# HDSC_HC32M140FX register map
Vendor: HDSC Co.Ltd; Series: ARMCM0P; File version: 1.2
CPU: CM0 r0p0, little endian, no MPU, no FPU, 3 interrupt priority bits
Registers are 8-bit, read-write, reset 0x0 unless marked. A register's access mark holds for its fields unless they carry their own. Offsets are from the block's base; [hi:lo] are bit positions; {n}, {i} and the like mark numbered series; 'fields as' and 'values as' point back to an identical list.

## CLOCK_COUNTER
Base 0x4003A000
0x00 CNTRD ro
  [5:0] CNT
0x01 CNTRL
  [5:0] RLC
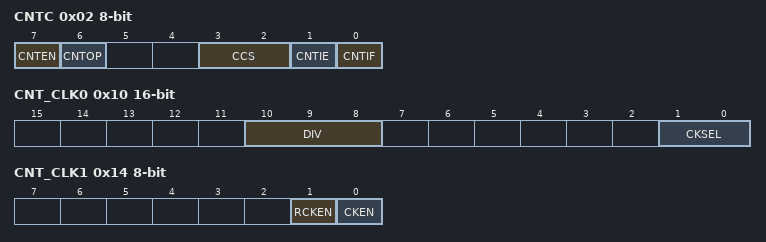
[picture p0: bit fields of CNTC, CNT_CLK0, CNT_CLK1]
0x02 CNTC
  [7] CNTEN, [6] CNTOP ro, [3:2] CCS, [1] CNTIE, [0] CNTIF
0x10 CNT_CLK0 16-bit
  [10:8] DIV, [1:0] CKSEL
0x14 CNT_CLK1
  [1] RCKEN ro, [0] CKEN

## CTIOSEL03
Base 0x40025100
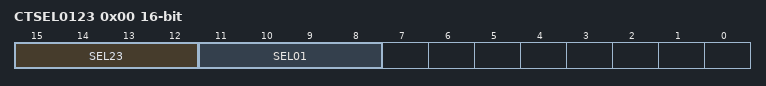
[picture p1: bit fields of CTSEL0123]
0x00 CTSEL0123 16-bit
  [15:12] SEL23, [11:8] SEL01

## CTSSSR
Base 0x40025F00
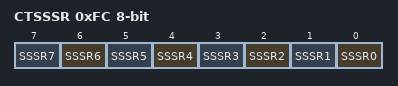
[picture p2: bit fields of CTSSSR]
0xFC CTSSSR
  [n] SSSR{n} wo (n=0..7)

## CT0_PPG — desc CT_PPG
Base 0x40025000
Same registers: CT1_PPG 0x40025040, CT2_PPG 0x40025080, CT3_PPG 0x400250C0
0x00 LWRR 16-bit
0x04 HWRR 16-bit
0x08 TCNT 16-bit ro
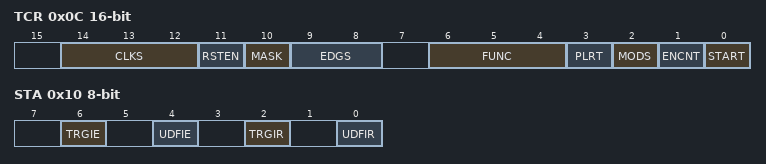
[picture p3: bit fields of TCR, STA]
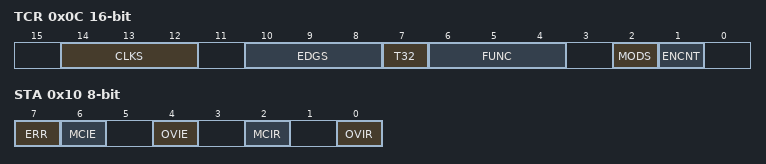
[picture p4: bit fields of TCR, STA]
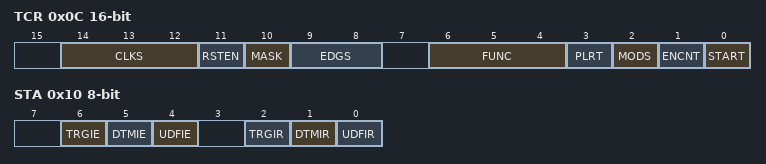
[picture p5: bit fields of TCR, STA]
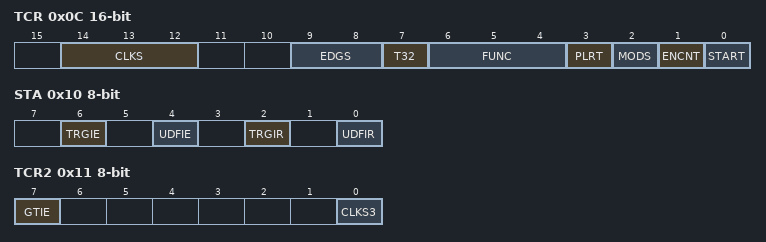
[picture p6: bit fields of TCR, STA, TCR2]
0x0C TCR 16-bit
  [14:12] CLKS, [11] RSTEN, [10] MASK, [9:8] EDGS, [6:4] FUNC, [3] PLRT, [2] MODS, [1] ENCNT, [0] START
0x10 STA
  [6] TRGIE, [4] UDFIE, [2] TRGIR, [0] UDFIR
0x11 TCR2
  [0] CLKS3

## CT0_PWC — desc CT_PWC
Base 0x40025000; alternate view of CT0_PPG
0x04 DBUF 16-bit ro (reset mask 0xFF)
0x0C TCR 16-bit
  [14:12] CLKS, [10:8] EDGS, [7] T32, [6:4] FUNC, [2] MODS, [1] ENCNT
0x10 STA
  [7] ERR ro, [6] MCIE, [4] OVIE, [2] MCIR ro, [0] OVIR
0x11 TCR2
  [0] CLKS3

## CT1_PWC — desc CT_PWC
Base 0x40025040; alternate view of CT1_PPG
Registers as CT0_PWC.

## CT2_PWC — desc CT_PWC
Base 0x40025080; alternate view of CT2_PPG
Registers as CT0_PWC.

## CT3_PWC — desc CT_PWC
Base 0x400250C0; alternate view of CT3_PPG
Registers as CT0_PWC.

## CT0_PWM — desc CT_PWM
Base 0x40025000; alternate view of CT0_PPG
0x00 CSR 16-bit
0x04 DUT 16-bit
0x08 TCNT 16-bit ro
0x0C TCR 16-bit
  [14:12] CLKS, [11] RSTEN, [10] MASK, [9:8] EDGS, [6:4] FUNC, [3] PLRT, [2] MODS, [1] ENCNT, [0] START
0x10 STA
  [6] TRGIE, [5] DTMIE, [4] UDFIE, [2] TRGIR, [1] DTMIR, [0] UDFIR
0x11 TCR2
  [0] CLKS3

## CT1_PWM — desc CT_PWM
Base 0x40025040; alternate view of CT1_PPG
Registers as CT0_PWM.

## CT2_PWM — desc CT_PWM
Base 0x40025080; alternate view of CT2_PPG
Registers as CT0_PWM.

## CT3_PWM — desc CT_PWM
Base 0x400250C0; alternate view of CT3_PPG
Registers as CT0_PWM.

## CT0_RT — desc CT_RT
Base 0x40025000; alternate view of CT0_PPG
0x00 CSR 16-bit
0x08 TCNT 16-bit ro
0x0C TCR 16-bit
  [14:12] CLKS, [9:8] EDGS, [7] T32, [6:4] FUNC, [3] PLRT, [2] MODS, [1] ENCNT, [0] START
0x10 STA
  [6] TRGIE, [4] UDFIE, [2] TRGIR, [0] UDFIR
0x11 TCR2
  [7] GTIE, [0] CLKS3

## CT1_RT — desc CT_RT
Base 0x40025040; alternate view of CT1_PPG
Registers as CT0_RT.

## CT2_RT — desc CT_RT
Base 0x40025080; alternate view of CT2_PPG
Registers as CT0_RT.

## CT3_RT — desc CT_RT
Base 0x400250C0; alternate view of CT3_PPG
Registers as CT0_RT.

## DMAC
Base 0x40060000
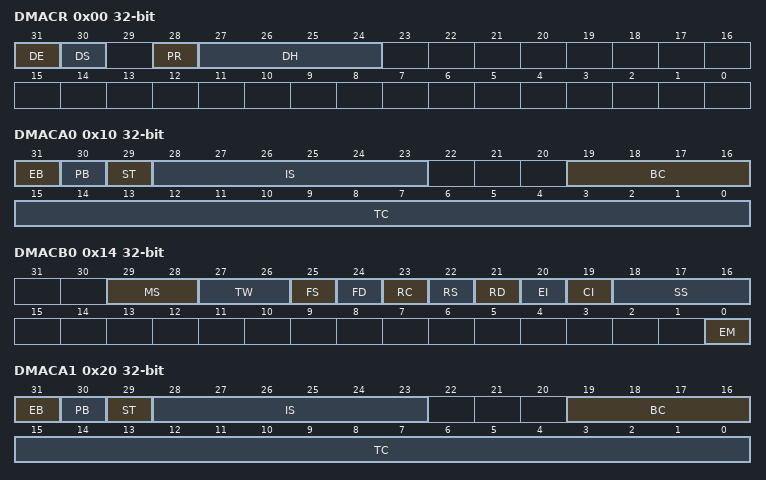
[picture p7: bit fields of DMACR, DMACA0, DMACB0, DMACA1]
0x00 DMACR 32-bit
  [31] DE, [30] DS ro, [28] PR, [27:24] DH
0x10 DMACA0 32-bit
  [31] EB, [30] PB, [29] ST, [28:23] IS, [19:16] BC, [15:0] TC
0x14 DMACB0 32-bit
  [29:28] MS, [27:26] TW, [25] FS, [24] FD, [23] RC, [22] RS, [21] RD, [20] EI, [19] CI, [18:16] SS, [0] EM
0x18 DMACSA0 32-bit
  [31:0] DMACSA
0x1C DMACDA0 32-bit
  [31:0] DMACDA
0x20 DMACA1 32-bit
  [31] EB, [30] PB, [29] ST, [28:23] IS, [19:16] BC, [15:0] TC
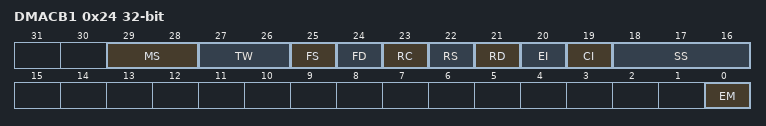
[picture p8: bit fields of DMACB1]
0x24 DMACB1 32-bit
  fields as DMACB0
0x28 DMACSA1 32-bit
  [31:0] DMACSA
0x2C DMACDA1 32-bit
  [31:0] DMACDA

## DTIM1 — desc DTIM
Base 0x40015000
Same registers: DTIM2 0x40015020
0x00 TIMERLOAD 32-bit
0x04 TIMERVALUE 32-bit ro reset 0xFFFFFFFF
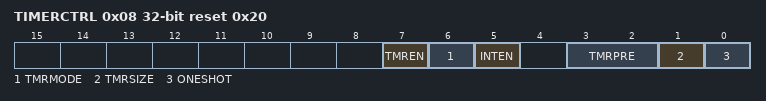
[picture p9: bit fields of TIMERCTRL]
0x08 TIMERCTRL 32-bit reset 0x20
  [7] TMREN, [6] TMRMODE, [5] INTEN, [3:2] TMRPRE, [1] TMRSIZE, [0] ONESHOT
0x0C TIMERINTCLR 32-bit wo
0x10 TIMERRIS 32-bit ro
  [0] TMRINTST
0x14 TIMERMIS 32-bit ro
  [0] TMRMINTST
0x18 TIMERBGLOAD 32-bit
